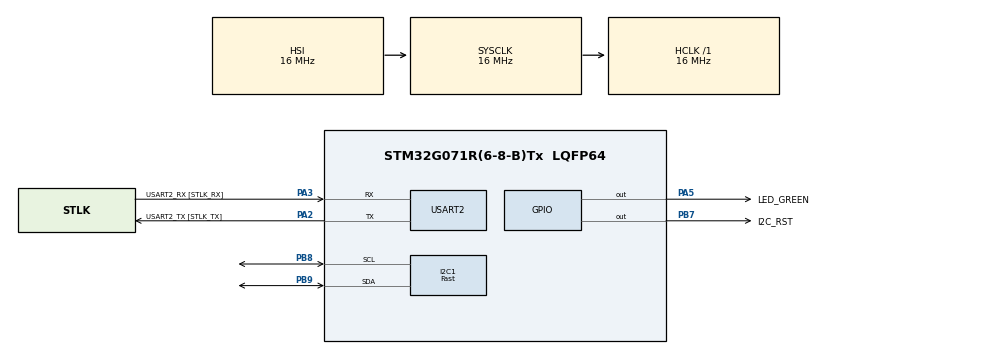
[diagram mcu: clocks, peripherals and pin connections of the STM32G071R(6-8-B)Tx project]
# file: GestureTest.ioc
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I2C1.I2C_Speed_Mode=I2C_Fast
I2C1.Timing=0x0010061A
Mcu.Family=STM32G0
Mcu.Name=STM32G071R(6-8-B)Tx
Mcu.Package=LQFP64
PA13.GPIO_Label=TMS
PA13.Mode=Serial_Wire
PA13.Signal=SYS_SWDIO
PA14-BOOT0.GPIO_Label=TCK
PA14-BOOT0.Mode=Serial_Wire
PA14-BOOT0.Signal=SYS_SWCLK
PA2.GPIO_Label=USART2_TX [STLK_TX]
PA2.GPIO_PuPd=GPIO_PULLUP
PA2.Mode=Asynchronous
PA2.Signal=USART2_TX
PA3.GPIO_Label=USART2_RX [STLK_RX]
PA3.GPIO_PuPd=GPIO_PULLUP
PA3.Mode=Asynchronous
PA3.Signal=USART2_RX
PA5.GPIO_Label=LED_GREEN
PA5.GPIO_Speed=GPIO_SPEED_FREQ_HIGH
PA5.Signal=GPIO_Output
PB7.GPIO_Label=I2C_RST
PB7.Signal=GPIO_Output
PB8.Mode=I2C
PB8.Signal=I2C1_SCL
PB9.Mode=I2C
PB9.Signal=I2C1_SDA
PC13.Mode=SYS_WakeUp1
PC13.Signal=SYS_WKUP2
PC14-OSC32_IN\ (PC14).Mode=LSE-External-Oscillator
PC14-OSC32_IN\ (PC14).Signal=RCC_OSC32_IN
PC15-OSC32_OUT\ (PC15).Mode=LSE-External-Oscillator
PC15-OSC32_OUT\ (PC15).Signal=RCC_OSC32_OUT
PF0-OSC_IN\ (PF0).GPIO_Label=MCO
PF0-OSC_IN\ (PF0).Mode=HSE-External-Clock-Source
PF0-OSC_IN\ (PF0).Signal=RCC_OSC_IN
ProjectManager.HeapSize=0x200
ProjectManager.StackSize=0x400
ProjectManager.TargetToolchain=STM32CubeIDE
RCC.AHBFreq_Value=16000000
RCC.CortexFreq_Value=16000000
RCC.EXTERNAL_CLOCK_VALUE=12288000
RCC.HCLKFreq_Value=16000000
RCC.HSE_VALUE=8000000
RCC.HSI_VALUE=16000000
RCC.SYSCLKFreq_VALUE=16000000
RCC.VCOOutputFreq_Value=128000000
USART2.VirtualMode-Asynchronous=VM_ASYNC
board=NUCLEO-G071RB

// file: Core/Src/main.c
/* USER CODE BEGIN Header */
/**
  ******************************************************************************
  * @file           : main.c
  * @brief          : Main program body
  ******************************************************************************
  * @attention
  *
  * Copyright (c) 2023 STMicroelectronics.
  * All rights reserved.
  *
  * This software is licensed under terms that can be found in the LICENSE file
  * in the root directory of this software component.
  * If no LICENSE file comes with this software, it is provided AS-IS.
  *
  ******************************************************************************
  */
/* USER CODE END Header */
#include "main.h"

I2C_HandleTypeDef hi2c1;

UART_HandleTypeDef huart2;

/* USER CODE BEGIN PV */
//VL53L5CX_Platform Sensor1;
VL53L5CX_Configuration Sensor1Cfg;
uint8_t is_alive;

/* USER CODE END PV */

void SystemClock_Config(void);
static void MX_GPIO_Init(void);
static void MX_USART2_UART_Init(void);
static void MX_I2C1_Init(void);

int main(void)
{
  /* USER CODE BEGIN 1 */
	is_alive = 0;
	Sensor1Cfg.platform.address = 0x52;
  /* USER CODE END 1 */

  /* MCU Configuration--------------------------------------------------------*/

  /* Reset of all peripherals, Initializes the Flash interface and the Systick. */
  HAL_Init();

  /* Configure the system clock */
  SystemClock_Config();

  /* Initialize all configured peripherals */
  MX_GPIO_Init();
  MX_USART2_UART_Init();
  MX_I2C1_Init();
  /* USER CODE BEGIN 2 */

  HAL_GPIO_WritePin(GPIOB, I2C_RST_Pin, GPIO_PIN_RESET);
  HAL_Delay(100);

  vl53l5cx_init(&Sensor1Cfg);
  HAL_Delay(1000);

  /* USER CODE END 2 */

  /* Infinite loop */
  /* USER CODE BEGIN WHILE */
  while (1)
  {
	  HAL_GPIO_TogglePin(GPIOA,LED_GREEN_Pin);
	  HAL_Delay(100);
	  vl53l5cx_is_alive(&Sensor1Cfg, &is_alive);
	  if (is_alive == 0){
		  HAL_GPIO_WritePin(GPIOA,LED_GREEN_Pin,GPIO_PIN_SET);
		  while(1){}
	  }

    /* USER CODE END WHILE */

  }
}

void SystemClock_Config(void)
{
  RCC_OscInitTypeDef RCC_OscInitStruct = {0};
  RCC_ClkInitTypeDef RCC_ClkInitStruct = {0};

  /** Configure the main internal regulator output voltage
  */
  HAL_PWREx_ControlVoltageScaling(PWR_REGULATOR_VOLTAGE_SCALE1);

  /** Initializes the RCC Oscillators according to the specified parameters
  * in the RCC_OscInitTypeDef structure.
  */
  RCC_OscInitStruct.OscillatorType = RCC_OSCILLATORTYPE_HSI;
  RCC_OscInitStruct.HSIState = RCC_HSI_ON;
  RCC_OscInitStruct.HSIDiv = RCC_HSI_DIV1;
  RCC_OscInitStruct.HSICalibrationValue = RCC_HSICALIBRATION_DEFAULT;
  RCC_OscInitStruct.PLL.PLLState = RCC_PLL_NONE;
  if (HAL_RCC_OscConfig(&RCC_OscInitStruct) != HAL_OK)
  {
    Error_Handler();
  }

  /** Initializes the CPU, AHB and APB buses clocks
  */
  RCC_ClkInitStruct.ClockType = RCC_CLOCKTYPE_HCLK|RCC_CLOCKTYPE_SYSCLK
                              |RCC_CLOCKTYPE_PCLK1;
  RCC_ClkInitStruct.SYSCLKSource = RCC_SYSCLKSOURCE_HSI;
  RCC_ClkInitStruct.AHBCLKDivider = RCC_SYSCLK_DIV1;
  RCC_ClkInitStruct.APB1CLKDivider = RCC_HCLK_DIV1;

  if (HAL_RCC_ClockConfig(&RCC_ClkInitStruct, FLASH_LATENCY_0) != HAL_OK)
  {
    Error_Handler();
  }
}

static void MX_I2C1_Init(void)
{

  hi2c1.Instance = I2C1;
  hi2c1.Init.Timing = 0x0010061A;
  hi2c1.Init.OwnAddress1 = 0;
  hi2c1.Init.AddressingMode = I2C_ADDRESSINGMODE_7BIT;
  hi2c1.Init.DualAddressMode = I2C_DUALADDRESS_DISABLE;
  hi2c1.Init.OwnAddress2 = 0;
  hi2c1.Init.OwnAddress2Masks = I2C_OA2_NOMASK;
  hi2c1.Init.GeneralCallMode = I2C_GENERALCALL_DISABLE;
  hi2c1.Init.NoStretchMode = I2C_NOSTRETCH_DISABLE;
  if (HAL_I2C_Init(&hi2c1) != HAL_OK)
  {
    Error_Handler();
  }

  /** Configure Analogue filter
  */
  if (HAL_I2CEx_ConfigAnalogFilter(&hi2c1, I2C_ANALOGFILTER_ENABLE) != HAL_OK)
  {
    Error_Handler();
  }

  /** Configure Digital filter
  */
  if (HAL_I2CEx_ConfigDigitalFilter(&hi2c1, 0) != HAL_OK)
  {
    Error_Handler();
  }

}

static void MX_USART2_UART_Init(void)
{

  huart2.Instance = USART2;
  huart2.Init.BaudRate = 115200;
  huart2.Init.WordLength = UART_WORDLENGTH_8B;
  huart2.Init.StopBits = UART_STOPBITS_1;
  huart2.Init.Parity = UART_PARITY_NONE;
  huart2.Init.Mode = UART_MODE_TX_RX;
  huart2.Init.HwFlowCtl = UART_HWCONTROL_NONE;
  huart2.Init.OverSampling = UART_OVERSAMPLING_16;
  huart2.Init.OneBitSampling = UART_ONE_BIT_SAMPLE_DISABLE;
  huart2.Init.ClockPrescaler = UART_PRESCALER_DIV1;
  huart2.AdvancedInit.AdvFeatureInit = UART_ADVFEATURE_NO_INIT;
  if (HAL_UART_Init(&huart2) != HAL_OK)
  {
    Error_Handler();
  }
  if (HAL_UARTEx_SetTxFifoThreshold(&huart2, UART_TXFIFO_THRESHOLD_1_8) != HAL_OK)
  {
    Error_Handler();
  }
  if (HAL_UARTEx_SetRxFifoThreshold(&huart2, UART_RXFIFO_THRESHOLD_1_8) != HAL_OK)
  {
    Error_Handler();
  }
  if (HAL_UARTEx_DisableFifoMode(&huart2) != HAL_OK)
  {
    Error_Handler();
  }

}

static void MX_GPIO_Init(void)
{
  GPIO_InitTypeDef GPIO_InitStruct = {0};

  /* GPIO Ports Clock Enable */
  __HAL_RCC_GPIOC_CLK_ENABLE();
  __HAL_RCC_GPIOF_CLK_ENABLE();
  __HAL_RCC_GPIOA_CLK_ENABLE();
  __HAL_RCC_GPIOB_CLK_ENABLE();
  __HAL_RCC_GPIOD_CLK_ENABLE();

  /*Configure GPIO pin Output Level */
  HAL_GPIO_WritePin(LED_GREEN_GPIO_Port, LED_GREEN_Pin, GPIO_PIN_RESET);

  /*Configure GPIO pin Output Level */
  HAL_GPIO_WritePin(I2C_RST_GPIO_Port, I2C_RST_Pin, GPIO_PIN_RESET);

  /*Configure GPIO pins : PC11 PC12 PC0 PC1
                           PC2 PC3 PC4 PC5
                           PC6 PC7 PC8 PC9
                           PC10 */
  GPIO_InitStruct.Pin = GPIO_PIN_11|GPIO_PIN_12|GPIO_PIN_0|GPIO_PIN_1
                          |GPIO_PIN_2|GPIO_PIN_3|GPIO_PIN_4|GPIO_PIN_5
                          |GPIO_PIN_6|GPIO_PIN_7|GPIO_PIN_8|GPIO_PIN_9
                          |GPIO_PIN_10;
  GPIO_InitStruct.Mode = GPIO_MODE_ANALOG;
  GPIO_InitStruct.Pull = GPIO_NOPULL;
  HAL_GPIO_Init(GPIOC, &GPIO_InitStruct);

  /*Configure GPIO pins : PF1 PF2 */
  GPIO_InitStruct.Pin = GPIO_PIN_1|GPIO_PIN_2;
  GPIO_InitStruct.Mode = GPIO_MODE_ANALOG;
  GPIO_InitStruct.Pull = GPIO_NOPULL;
  HAL_GPIO_Init(GPIOF, &GPIO_InitStruct);

  /*Configure GPIO pins : PA0 PA1 PA4 PA6
                           PA7 PA8 PA9 PA10
                           PA11 PA12 PA15 */
  GPIO_InitStruct.Pin = GPIO_PIN_0|GPIO_PIN_1|GPIO_PIN_4|GPIO_PIN_6
                          |GPIO_PIN_7|GPIO_PIN_8|GPIO_PIN_9|GPIO_PIN_10
                          |GPIO_PIN_11|GPIO_PIN_12|GPIO_PIN_15;
  GPIO_InitStruct.Mode = GPIO_MODE_ANALOG;
  GPIO_InitStruct.Pull = GPIO_NOPULL;
  HAL_GPIO_Init(GPIOA, &GPIO_InitStruct);

  /*Configure GPIO pin : LED_GREEN_Pin */
  GPIO_InitStruct.Pin = LED_GREEN_Pin;
  GPIO_InitStruct.Mode = GPIO_MODE_OUTPUT_PP;
  GPIO_InitStruct.Pull = GPIO_NOPULL;
  GPIO_InitStruct.Speed = GPIO_SPEED_FREQ_HIGH;
  HAL_GPIO_Init(LED_GREEN_GPIO_Port, &GPIO_InitStruct);

  /*Configure GPIO pins : PB0 PB1 PB2 PB10
                           PB11 PB12 PB13 PB14
                           PB15 PB3 PB4 PB5
                           PB6 */
  GPIO_InitStruct.Pin = GPIO_PIN_0|GPIO_PIN_1|GPIO_PIN_2|GPIO_PIN_10
                          |GPIO_PIN_11|GPIO_PIN_12|GPIO_PIN_13|GPIO_PIN_14
                          |GPIO_PIN_15|GPIO_PIN_3|GPIO_PIN_4|GPIO_PIN_5
                          |GPIO_PIN_6;
  GPIO_InitStruct.Mode = GPIO_MODE_ANALOG;
  GPIO_InitStruct.Pull = GPIO_NOPULL;
  HAL_GPIO_Init(GPIOB, &GPIO_InitStruct);

  /*Configure GPIO pins : PD8 PD9 PD0 PD1
                           PD2 PD3 PD4 PD5
                           PD6 */
  GPIO_InitStruct.Pin = GPIO_PIN_8|GPIO_PIN_9|GPIO_PIN_0|GPIO_PIN_1
                          |GPIO_PIN_2|GPIO_PIN_3|GPIO_PIN_4|GPIO_PIN_5
                          |GPIO_PIN_6;
  GPIO_InitStruct.Mode = GPIO_MODE_ANALOG;
  GPIO_InitStruct.Pull = GPIO_NOPULL;
  HAL_GPIO_Init(GPIOD, &GPIO_InitStruct);

  /*Configure GPIO pin : I2C_RST_Pin */
  GPIO_InitStruct.Pin = I2C_RST_Pin;
  GPIO_InitStruct.Mode = GPIO_MODE_OUTPUT_PP;
  GPIO_InitStruct.Pull = GPIO_NOPULL;
  GPIO_InitStruct.Speed = GPIO_SPEED_FREQ_LOW;
  HAL_GPIO_Init(I2C_RST_GPIO_Port, &GPIO_InitStruct);

}

void Error_Handler(void)
{
  __disable_irq();
  while (1)
  {
  }
}
